VERSION ""

NS_ :

BS_:

BU_: XXX

BO_ 374 NEW_MSG_1: 8 XXX
 SG_ NEW_SIGNAL_1 : 23|16@0+ (1,0) [0|65535] "" XXX
 SG_ SPEED_MAYBE : 7|16@0+ (1,0) [0|65535] "" XXX

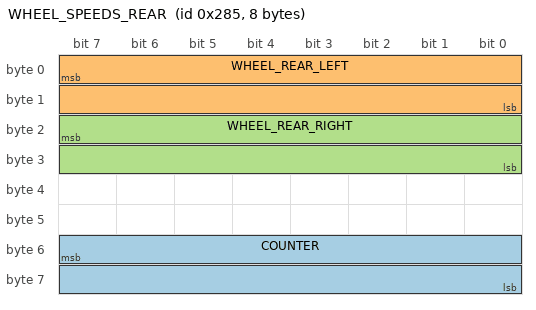
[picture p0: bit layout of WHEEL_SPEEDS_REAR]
BO_ 645 WHEEL_SPEEDS_REAR: 8 XXX
 SG_ COUNTER : 55|16@0+ (1,0) [0|65535] "" XXX
 SG_ WHEEL_REAR_LEFT : 7|16@0+ (1,0) [0|65535] "" XXX
 SG_ WHEEL_REAR_RIGHT : 23|16@0+ (1,0) [0|65535] "" XXX

BO_ 384 NEW_MSG_2: 8 XXX
 SG_ NEW_SIGNAL_1 : 7|16@0+ (1,0) [0|65535] "" XXX

BO_ 861 WIPER: 8 XXX
 SG_ NEW_SIGNAL_1 : 39|8@0+ (1,0) [0|255] "" XXX

BO_ 2 POWER_STEERING: 8 XXX
 SG_ STEERING_ANGLE : 0|16@1- (1,0) [0|65535] "" XXX

BO_ 644 WHEEL_SPEEDS_FRONT: 8 XXX
 SG_ WHEEL_FRONT_LEFT : 7|16@0+ (1,0) [0|65535] "" XXX
 SG_ WHEEL_FRONT_RIGHT : 23|16@0+ (1,0) [0|65535] "" XXX

BO_ 375 Gear byte 1 fe drive 5a rev: 8 XXX
